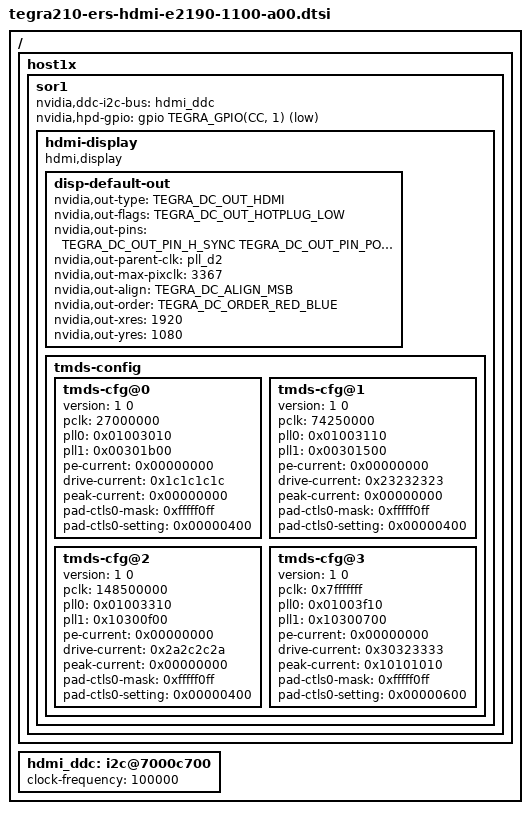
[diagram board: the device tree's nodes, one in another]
/*
 * arch/arm64/boot/dts/tegra210-platforms/tegra210-ers-hdmi-e2190-1100-a00.dtsi
 *
 * Copyright (c) 2014, NVIDIA CORPORATION.  All rights reserved.
 *
 * This program is free software; you can redistribute it and/or modify
 * it under the terms of the GNU General Public License as published by
 * the Free Software Foundation; either version 2 of the License, or
 * (at your option) any later version.
 *
 * This program is distributed in the hope that it will be useful, but WITHOUT
 * ANY WARRANTY; without even the implied warranty of MERCHANTABILITY or
 * FITNESS FOR A PARTICULAR PURPOSE.  See the GNU General Public License for
 * more details.
 *
 * You should have received a copy of the GNU General Public License along
 * with this program; if not, write to the Free Software Foundation, Inc.,
 * 51 Franklin Street, Fifth Floor, Boston, MA  02110-1301, USA.
 */

#include <dt-bindings/display/tegra-dc.h>

/ {
	host1x {
		sor1 {
			status = "okay";
			nvidia,ddc-i2c-bus = <&hdmi_ddc>;
			nvidia,hpd-gpio = <&gpio TEGRA_GPIO(CC, 1) 1>; /* PN7 */
			hdmi-display {
				status = "okay";
				compatible = "hdmi,display";
				disp-default-out {
					nvidia,out-type = <TEGRA_DC_OUT_HDMI>;
					nvidia,out-flags = <TEGRA_DC_OUT_HOTPLUG_LOW>;
					nvidia,out-pins = <TEGRA_DC_OUT_PIN_H_SYNC TEGRA_DC_OUT_PIN_POL_LOW
							   TEGRA_DC_OUT_PIN_V_SYNC TEGRA_DC_OUT_PIN_POL_LOW
							   TEGRA_DC_OUT_PIN_DATA_ENABLE TEGRA_DC_OUT_PIN_POL_HIGH>;
					nvidia,out-parent-clk = "pll_d2";
					nvidia,out-max-pixclk = <3367>; /* KHZ2PICOS(297000) */
					nvidia,out-align = <TEGRA_DC_ALIGN_MSB>;
					nvidia,out-order = <TEGRA_DC_ORDER_RED_BLUE>;
					nvidia,out-xres = <1920>;
					nvidia,out-yres = <1080>;
				};
				tmds-config {
					tmds-cfg@0 {
						version = <1 0>;
						pclk = <27000000>;
						pll0 = <0x01003010>;
						pll1 = <0x00301b00>;
						pe-current = <0x00000000>;
						drive-current = <0x1c1c1c1c>;
						peak-current = <0x00000000>;
						pad-ctls0-mask = <0xfffff0ff>;
						pad-ctls0-setting = <0x00000400>;
					};
					tmds-cfg@1 {
						version = <1 0>;
						pclk = <74250000>;
						pll0 = <0x01003110>;
						pll1 = <0x00301500>;
						pe-current = <0x00000000>;
						drive-current = <0x23232323>;
						peak-current = <0x00000000>;
						pad-ctls0-mask = <0xfffff0ff>;
						pad-ctls0-setting = <0x00000400>;
					};
					tmds-cfg@2 {
						version = <1 0>;
						pclk = <148500000>;
						pll0 = <0x01003310>;
						pll1 = <0x10300f00>;
						pe-current = <0x00000000>;
						drive-current = <0x2a2c2c2a>;
						peak-current = <0x00000000>;
						pad-ctls0-mask = <0xfffff0ff>;
						pad-ctls0-setting = <0x00000400>;
					};
					tmds-cfg@3 {
						version = <1 0>;
						pclk = <0x7fffffff>;
						pll0 = <0x01003f10>;
						pll1 = <0x10300700>;
						pe-current = <0x00000000>;
						drive-current = <0x30323333>;
						peak-current = <0x10101010>;
						pad-ctls0-mask = <0xfffff0ff>;
						pad-ctls0-setting = <0x00000600>;
					};
				};
			};
		};
	};
	hdmi_ddc: i2c@7000c700 {
		clock-frequency = <100000>;
	};
};
